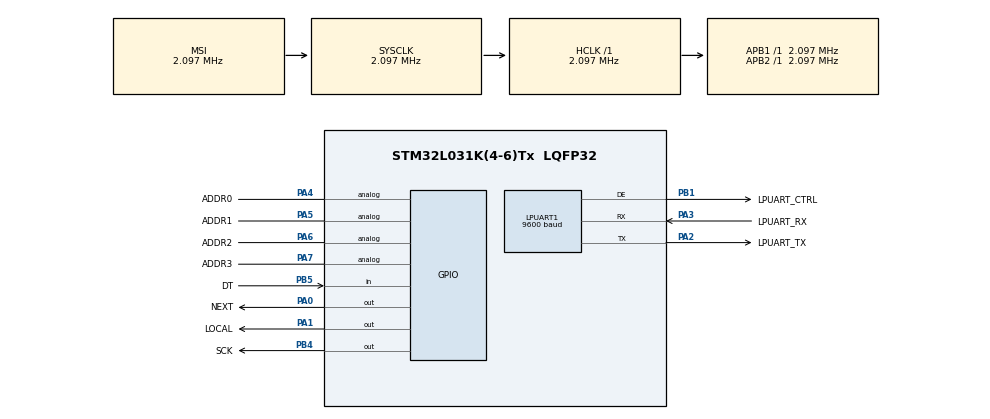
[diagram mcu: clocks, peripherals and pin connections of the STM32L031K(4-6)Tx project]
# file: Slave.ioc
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Dma.LPUART1_RX.0.Direction=DMA_PERIPH_TO_MEMORY
Dma.LPUART1_RX.0.Instance=DMA1_Channel3
Dma.LPUART1_RX.0.MemDataAlignment=DMA_MDATAALIGN_BYTE
Dma.LPUART1_RX.0.MemInc=DMA_MINC_ENABLE
Dma.LPUART1_RX.0.Mode=DMA_NORMAL
Dma.LPUART1_RX.0.PeriphDataAlignment=DMA_PDATAALIGN_BYTE
Dma.LPUART1_RX.0.PeriphInc=DMA_PINC_DISABLE
Dma.LPUART1_RX.0.Priority=DMA_PRIORITY_LOW
Dma.LPUART1_TX.1.Direction=DMA_MEMORY_TO_PERIPH
Dma.LPUART1_TX.1.Instance=DMA1_Channel2
Dma.LPUART1_TX.1.MemDataAlignment=DMA_MDATAALIGN_BYTE
Dma.LPUART1_TX.1.MemInc=DMA_MINC_ENABLE
Dma.LPUART1_TX.1.Mode=DMA_NORMAL
Dma.LPUART1_TX.1.PeriphDataAlignment=DMA_PDATAALIGN_BYTE
Dma.LPUART1_TX.1.PeriphInc=DMA_PINC_DISABLE
Dma.LPUART1_TX.1.Priority=DMA_PRIORITY_LOW
Dma.Request0=LPUART1_RX
Dma.Request1=LPUART1_TX
LPUART1.BaudRate=9600
LPUART1.WordLength=UART_WORDLENGTH_8B
Mcu.Family=STM32L0
Mcu.Name=STM32L031K(4-6)Tx
Mcu.Package=LQFP32
NVIC.DMA1_Channel2_3_IRQn=true\:0\:0\:false\:false\:true\:false\:true\:true
NVIC.LPUART1_IRQn=true\:0\:0\:false\:false\:true\:false\:true\:true
PA0.GPIO_Label=NEXT
PA0.PinState=GPIO_PIN_SET
PA0.Signal=GPIO_Output
PA1.GPIO_Label=LOCAL
PA1.Signal=GPIO_Output
PA13.Mode=Serial_Wire
PA13.Signal=SYS_SWDIO
PA14.Mode=Serial_Wire
PA14.Signal=SYS_SWCLK
PA2.GPIO_Label=LPUART_TX
PA2.Mode=Asynchronous
PA2.Signal=LPUART1_TX
PA3.GPIO_Label=LPUART_RX
PA3.GPIO_PuPd=GPIO_PULLUP
PA3.Mode=Asynchronous
PA3.Signal=LPUART1_RX
PA4.GPIO_Label=ADDR0
PA4.Signal=GPIO_Analog
PA5.GPIO_Label=ADDR1
PA5.Signal=GPIO_Analog
PA6.GPIO_Label=ADDR2
PA6.Signal=GPIO_Analog
PA7.GPIO_Label=ADDR3
PA7.Signal=GPIO_Analog
PB1.GPIO_Label=LPUART_CTRL
PB1.Mode=Hardware Flow Control (RS485)
PB1.Signal=LPUART1_DE
PB4.GPIO_Label=SCK
PB4.Signal=GPIO_Output
PB5.GPIO_Label=DT
PB5.Signal=GPIO_Input
ProjectManager.HeapSize=0x200
ProjectManager.StackSize=0x400
ProjectManager.TargetToolchain=CMake
RCC.AHBFreq_Value=2097000
RCC.APB1Freq_Value=2097000
RCC.APB1TimFreq_Value=2097000
RCC.APB2Freq_Value=2097000
RCC.APB2TimFreq_Value=2097000
RCC.HSE_VALUE=8000000
RCC.HSI16_VALUE=16000000
RCC.HSI_VALUE=16000000
RCC.LSE_VALUE=32768
RCC.MSI_VALUE=2097000
RCC.PWR_Regulator_Voltage_Scale=PWR_REGULATOR_VOLTAGE_SCALE2
RCC.SYSCLKFreq_VALUE=2097000
RCC.VCOOutputFreq_Value=48000000
board=custom

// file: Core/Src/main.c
/* USER CODE BEGIN Header */
/**
  ******************************************************************************
  * @file           : main.c
  * @brief          : Main program body
  ******************************************************************************
  * @attention
  *
  * Copyright (c) 2026 STMicroelectronics.
  * All rights reserved.
  *
  * This software is licensed under terms that can be found in the LICENSE file
  * in the root directory of this software component.
  * If no LICENSE file comes with this software, it is provided AS-IS.
  *
  ******************************************************************************
  */
/* USER CODE END Header */
#include "main.h"
#include "dma.h"
#include "usart.h"
#include "gpio.h"

/* USER CODE BEGIN Includes */
#include "nest.h"
/* USER CODE END Includes */

void SystemClock_Config(void);

int main(void)
{

  /* MCU Configuration--------------------------------------------------------*/

  /* Reset of all peripherals, Initializes the Flash interface and the Systick. */
  HAL_Init();

  /* Configure the system clock */
  SystemClock_Config();

  /* Initialize all configured peripherals */
  MX_GPIO_Init();
  MX_DMA_Init();
  MX_LPUART1_UART_Init();
  /* USER CODE BEGIN 2 */
  Nest_Init();
  /* USER CODE END 2 */

  /* Infinite loop */
  while (1)
  {

    /* USER CODE BEGIN 3 */
    Nest_Process();
  }
  /* USER CODE END 3 */
}

void SystemClock_Config(void)
{
  RCC_OscInitTypeDef RCC_OscInitStruct = {0};
  RCC_ClkInitTypeDef RCC_ClkInitStruct = {0};
  RCC_PeriphCLKInitTypeDef PeriphClkInit = {0};

  /** Configure the main internal regulator output voltage
  */
  __HAL_PWR_VOLTAGESCALING_CONFIG(PWR_REGULATOR_VOLTAGE_SCALE2);

  /** Initializes the RCC Oscillators according to the specified parameters
  * in the RCC_OscInitTypeDef structure.
  */
  RCC_OscInitStruct.OscillatorType = RCC_OSCILLATORTYPE_MSI;
  RCC_OscInitStruct.MSIState = RCC_MSI_ON;
  RCC_OscInitStruct.MSICalibrationValue = 0;
  RCC_OscInitStruct.MSIClockRange = RCC_MSIRANGE_5;
  RCC_OscInitStruct.PLL.PLLState = RCC_PLL_NONE;
  if (HAL_RCC_OscConfig(&RCC_OscInitStruct) != HAL_OK)
  {
    Error_Handler();
  }

  /** Initializes the CPU, AHB and APB buses clocks
  */
  RCC_ClkInitStruct.ClockType = RCC_CLOCKTYPE_HCLK|RCC_CLOCKTYPE_SYSCLK
                              |RCC_CLOCKTYPE_PCLK1|RCC_CLOCKTYPE_PCLK2;
  RCC_ClkInitStruct.SYSCLKSource = RCC_SYSCLKSOURCE_MSI;
  RCC_ClkInitStruct.AHBCLKDivider = RCC_SYSCLK_DIV1;
  RCC_ClkInitStruct.APB1CLKDivider = RCC_HCLK_DIV1;
  RCC_ClkInitStruct.APB2CLKDivider = RCC_HCLK_DIV1;

  if (HAL_RCC_ClockConfig(&RCC_ClkInitStruct, FLASH_LATENCY_0) != HAL_OK)
  {
    Error_Handler();
  }
  PeriphClkInit.PeriphClockSelection = RCC_PERIPHCLK_LPUART1;
  PeriphClkInit.Lpuart1ClockSelection = RCC_LPUART1CLKSOURCE_PCLK1;
  if (HAL_RCCEx_PeriphCLKConfig(&PeriphClkInit) != HAL_OK)
  {
    Error_Handler();
  }
}

void Error_Handler(void)
{
  /* USER CODE BEGIN Error_Handler_Debug */
  __disable_irq();
  NVIC_SystemReset();
  /* USER CODE END Error_Handler_Debug */
}
